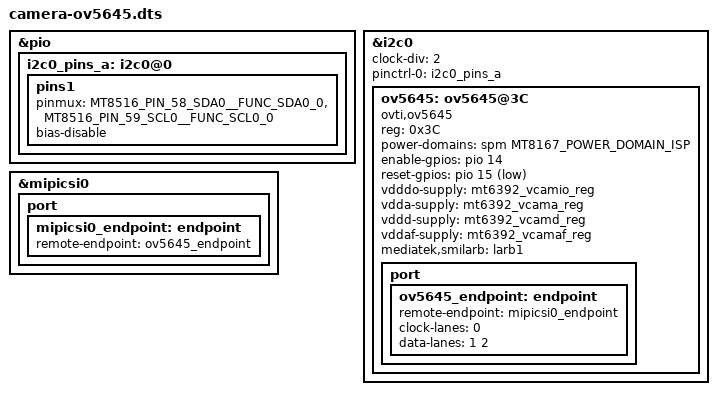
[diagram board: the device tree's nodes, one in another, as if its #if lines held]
// SPDX-License-Identifier: GPL-2.0
/*
 * Copyright (c) 2020 BayLibre, SAS.
 * Author: Florian Sylvestre <fsylvestre@baylibre.com>
 */

#include <dt-bindings/power/mt8167-power.h>
#include <dt-bindings/gpio/gpio.h>
#include <uapi/linux/version.h>
#include "mt8516-pinfunc.h"

/dts-v1/;
/plugin/;

/ {
	fragment@0 {
		target = <&pio>;
		__overlay__ {
			i2c0_pins_a: i2c0@0 {
				pins1 {
					pinmux = <MT8516_PIN_58_SDA0__FUNC_SDA0_0>,
							 <MT8516_PIN_59_SCL0__FUNC_SCL0_0>;
					bias-disable;
				};
			};
		};
	};

	fragment@1 {
		target = <&i2c0>;
		__overlay__ {
			clock-div = <2>;
			pinctrl-names = "default";
			pinctrl-0 = <&i2c0_pins_a>;
			status = "okay";

			ov5645: ov5645@3C {
				compatible = "ovti,ov5645";
				reg = <0x3C>;
#if (LINUX_VERSION_CODE >= KERNEL_VERSION(5,10,0))
				power-domains = <&spm MT8167_POWER_DOMAIN_ISP>;
#else
				power-domains = <&scpsys MT8167_POWER_DOMAIN_ISP>;
#endif

				enable-gpios = <&pio 14 GPIO_ACTIVE_HIGH>;
				reset-gpios = <&pio 15 GPIO_ACTIVE_LOW>;

				vdddo-supply = <&mt6392_vcamio_reg>;
				vdda-supply = <&mt6392_vcama_reg>;
				vddd-supply = <&mt6392_vcamd_reg>;
				vddaf-supply = <&mt6392_vcamaf_reg>;

				mediatek,smilarb = <&larb1>;

				status = "okay";

				port {
					ov5645_endpoint: endpoint {
						remote-endpoint = <&mipicsi0_endpoint>;
						clock-lanes = <0>;
						data-lanes = <1 2>;
					};
				};
			};
		};
	};

	fragment@2 {
		target = <&mipicsi0>;
		__overlay__ {
			status = "okay";

			port {
				mipicsi0_endpoint: endpoint {
					remote-endpoint = <&ov5645_endpoint>;
				};
			};
		};
	};
};
